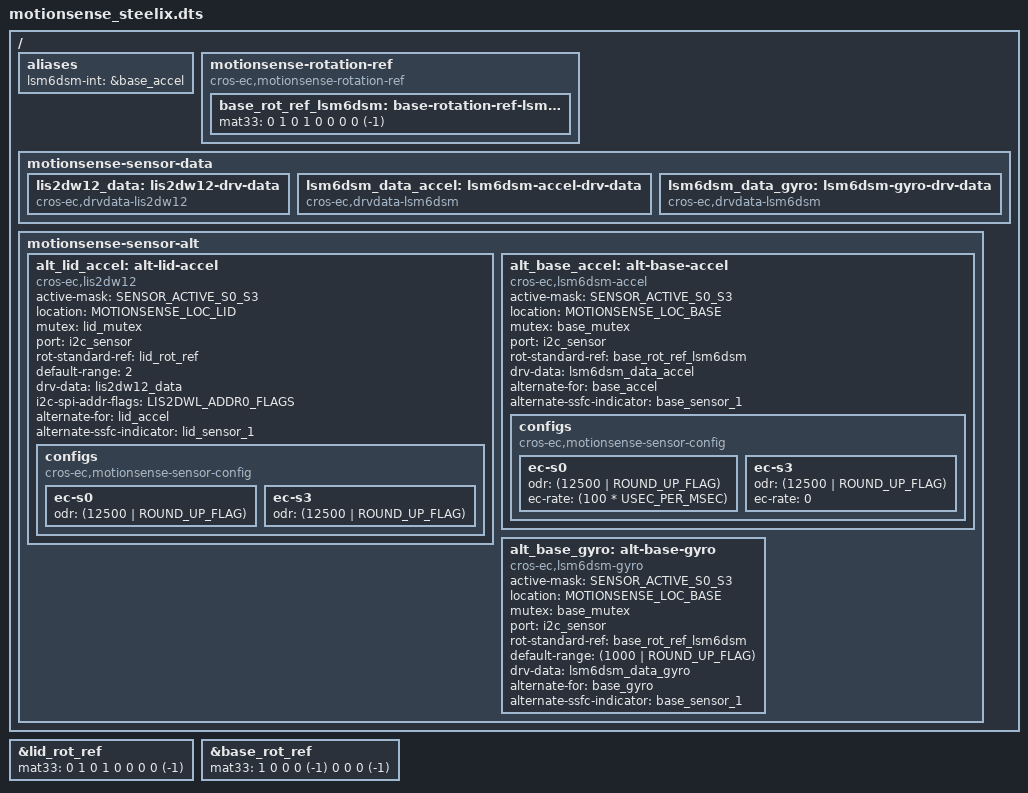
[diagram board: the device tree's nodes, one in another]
/* Copyright 2022 The ChromiumOS Authors
 * Use of this source code is governed by a BSD-style license that can be
 * found in the LICENSE file.
 */

#include <dt-bindings/motionsense/utils.h>

/* inherit the rot_ref from Kingler and overwrite it */
&lid_rot_ref {
	mat33 = <0 1 0
		1 0 0
		0 0 (-1)>;
};

&base_rot_ref {
	mat33 = <1 0 0
		0 (-1) 0
		0 0 (-1)>;
};

/ {
	aliases {
		/*
		 * motion sense's <>_INT_EVENT is handled
		 * by alias. Using the alias, each driver creates
		 * its own <>_INT_EVENT.
		 */
		lsm6dsm-int = &base_accel;
	};

	/* Rotation matrix used by drivers. */
	motionsense-rotation-ref {
		compatible = "cros-ec,motionsense-rotation-ref";
		base_rot_ref_lsm6dsm: base-rotation-ref-lsm6dsm {
			mat33 = <0 1 0
				 1 0 0
				 0 0 (-1)>;
		};
	};

	/*
	 * Driver specific data. A driver-specific data can be shared with
	 * different motion sensors while they are using the same driver.
	 *
	 * If a node's compatible starts with "cros-ec,accelgyro-", it is for
	 * a common structure defined in accelgyro.h.
	 * e.g) compatible = "cros-ec,accelgyro-als-drv-data" is for
	 * "struct als_drv_data_t" in accelgyro.h
	 */
	motionsense-sensor-data {
		lis2dw12_data: lis2dw12-drv-data {
			compatible = "cros-ec,drvdata-lis2dw12";
			status = "okay";
		};
		lsm6dsm_data_accel: lsm6dsm-accel-drv-data {
			compatible = "cros-ec,drvdata-lsm6dsm";
			status = "okay";
		};
		lsm6dsm_data_gyro: lsm6dsm-gyro-drv-data {
			compatible = "cros-ec,drvdata-lsm6dsm";
			status = "okay";
		};
	};

	motionsense-sensor-alt {
		alt_lid_accel: alt-lid-accel {
			compatible = "cros-ec,lis2dw12";
			status = "okay";

			active-mask = "SENSOR_ACTIVE_S0_S3";
			location = "MOTIONSENSE_LOC_LID";
			mutex = <&lid_mutex>;
			port = <&i2c_sensor>;
			rot-standard-ref = <&lid_rot_ref>;
			default-range = <2>;
			drv-data = <&lis2dw12_data>;
			i2c-spi-addr-flags = "LIS2DWL_ADDR0_FLAGS";
			alternate-for = <&lid_accel>;
			alternate-ssfc-indicator = <&lid_sensor_1>;
			configs {
				compatible =
					"cros-ec,motionsense-sensor-config";
				ec-s0 {
					odr = <(12500 | ROUND_UP_FLAG)>;
				};
				ec-s3 {
					odr = <(12500 | ROUND_UP_FLAG)>;
				};
			};
		};

		alt_base_accel: alt-base-accel {
			compatible = "cros-ec,lsm6dsm-accel";
			status = "okay";

			active-mask = "SENSOR_ACTIVE_S0_S3";
			location = "MOTIONSENSE_LOC_BASE";
			mutex = <&base_mutex>;
			port = <&i2c_sensor>;
			rot-standard-ref = <&base_rot_ref_lsm6dsm>;
			drv-data = <&lsm6dsm_data_accel>;
			alternate-for = <&base_accel>;
			alternate-ssfc-indicator = <&base_sensor_1>;
			configs {
				compatible =
					"cros-ec,motionsense-sensor-config";
				ec-s0 {
					odr = <(12500 | ROUND_UP_FLAG)>;
					ec-rate = <(100 * USEC_PER_MSEC)>;
				};
				ec-s3 {
					odr = <(12500 | ROUND_UP_FLAG)>;
					ec-rate = <0>;
				};
			};
		};

		alt_base_gyro: alt-base-gyro {
			compatible = "cros-ec,lsm6dsm-gyro";
			status = "okay";

			active-mask = "SENSOR_ACTIVE_S0_S3";
			location = "MOTIONSENSE_LOC_BASE";
			mutex = <&base_mutex>;
			port = <&i2c_sensor>;
			rot-standard-ref = <&base_rot_ref_lsm6dsm>;
			default-range = <(1000 | ROUND_UP_FLAG)>; /* dps */
			drv-data = <&lsm6dsm_data_gyro>;
			alternate-for = <&base_gyro>;
			alternate-ssfc-indicator = <&base_sensor_1>;
		};
	};
};
